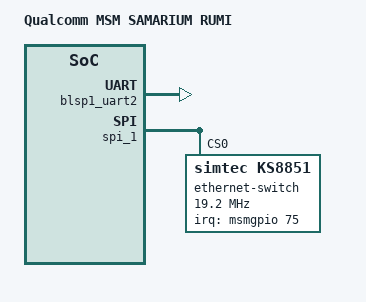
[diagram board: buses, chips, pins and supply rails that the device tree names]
/* Copyright (c) 2013, The Linux Foundation. All rights reserved.
 *
 * This program is free software; you can redistribute it and/or modify
 * it under the terms of the GNU General Public License version 2 and
 * only version 2 as published by the Free Software Foundation.
 *
 * This program is distributed in the hope that it will be useful,
 * but WITHOUT ANY WARRANTY; without even the implied warranty of
 * MERCHANTABILITY or FITNESS FOR A PARTICULAR PURPOSE.  See the
 * GNU General Public License for more details.
 */

/dts-v1/;

/include/ "msmsamarium.dtsi"

/ {
	model = "Qualcomm MSM SAMARIUM RUMI";
	compatible = "qcom,msmsamarium-rumi", "qcom,msmsamarium", "qcom,rumi";
	qcom,board-id = <15 0>;
};

&blsp1_uart2{
	status = "ok";
};

&spi_1 {
		ethernet-switch@0 {
			compatible = "simtec,ks8851";
			reg = <0>;
			interrupt-parent = <&msmgpio>;
			interrupts = <75 0>;
			spi-max-frequency = <19200000>;
		};
};
